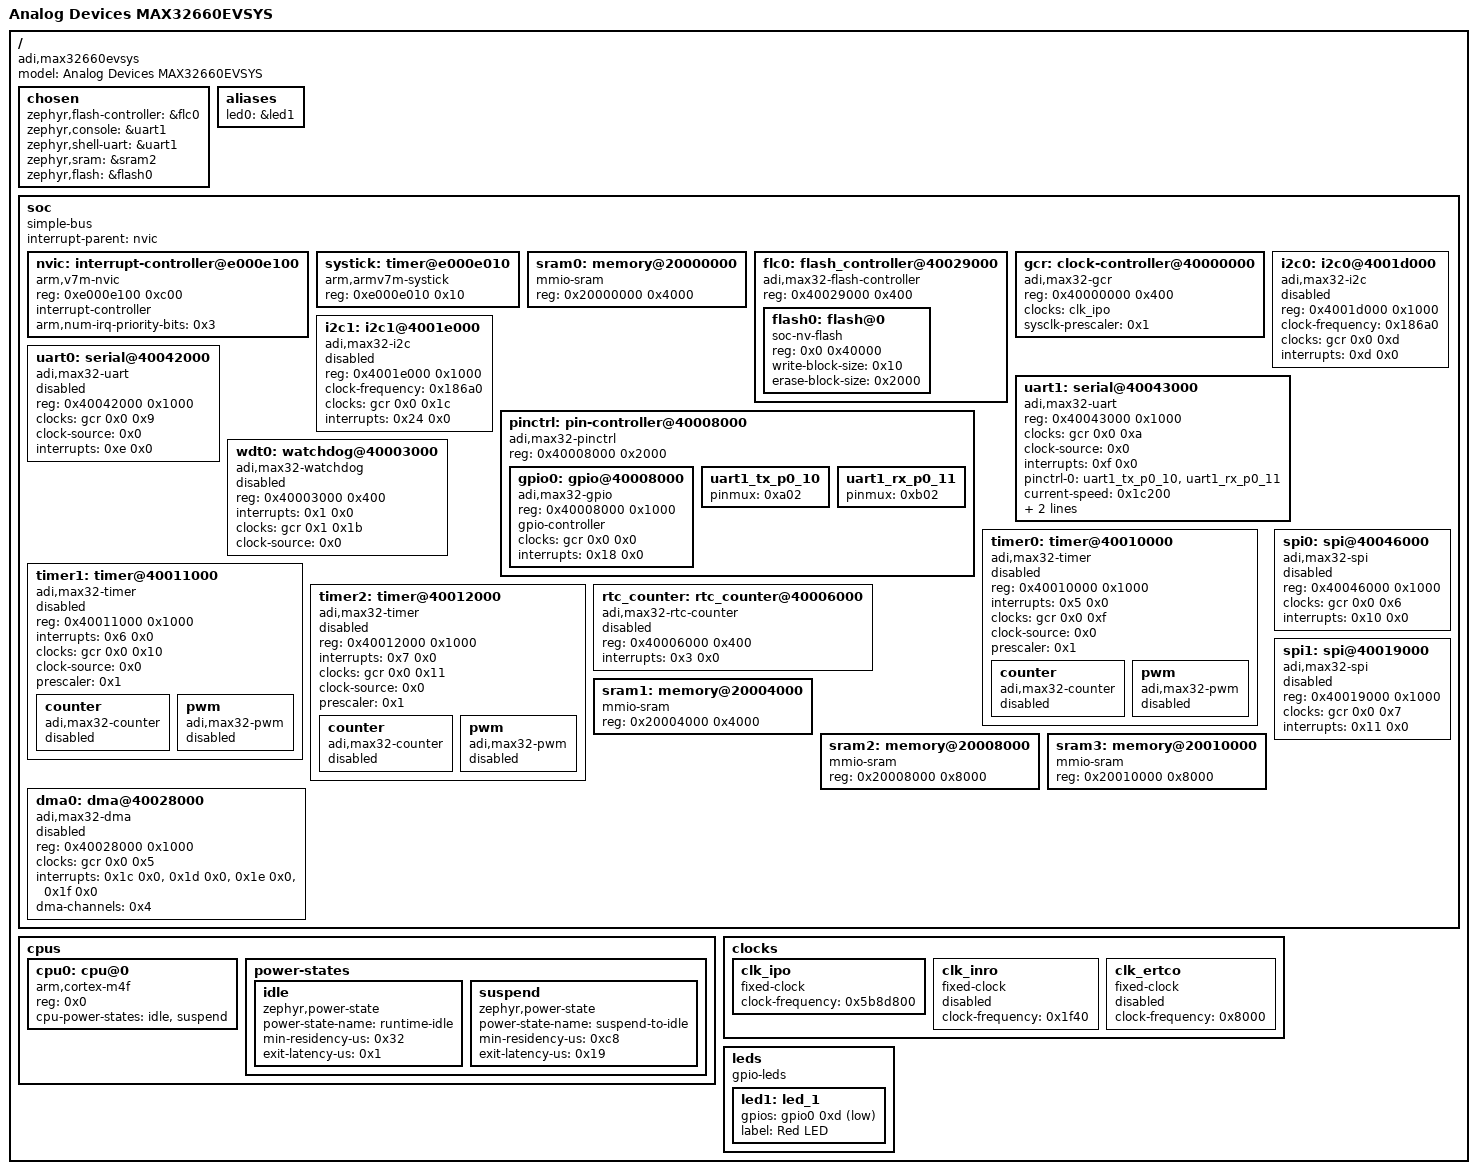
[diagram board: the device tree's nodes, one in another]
/dts-v1/;

/* node '/' defined in zephyr/dts/common/skeleton.dtsi:9 */
/ {
	#address-cells = < 0x1 >;               /* in zephyr/dts/common/skeleton.dtsi:10 */
	#size-cells = < 0x1 >;                  /* in zephyr/dts/common/skeleton.dtsi:11 */
	model = "Analog Devices MAX32660EVSYS"; /* in zephyr/boards/adi/max32660evsys/max32660evsys.dts:15 */
	compatible = "adi,max32660evsys";       /* in zephyr/boards/adi/max32660evsys/max32660evsys.dts:16 */

	/* node '/chosen' defined in zephyr/dts/common/skeleton.dtsi:13 */
	chosen {
		zephyr,flash-controller = &flc0; /* in zephyr/dts/arm/adi/max32/max32xxx.dtsi:18 */
		zephyr,console = &uart1;         /* in zephyr/boards/adi/max32660evsys/max32660evsys.dts:19 */
		zephyr,shell-uart = &uart1;      /* in zephyr/boards/adi/max32660evsys/max32660evsys.dts:20 */
		zephyr,sram = &sram2;            /* in zephyr/boards/adi/max32660evsys/max32660evsys.dts:21 */
		zephyr,flash = &flash0;          /* in zephyr/boards/adi/max32660evsys/max32660evsys.dts:22 */
	};

	/* node '/aliases' defined in zephyr/dts/common/skeleton.dtsi:15 */
	aliases {
		led0 = &led1; /* in zephyr/boards/adi/max32660evsys/max32660evsys.dts:36 */
	};

	/* node '/soc' defined in zephyr/dts/arm/armv7-m.dtsi:6 */
	soc {
		#address-cells = < 0x1 >;     /* in zephyr/dts/arm/armv7-m.dtsi:7 */
		#size-cells = < 0x1 >;        /* in zephyr/dts/arm/armv7-m.dtsi:8 */
		compatible = "simple-bus";    /* in zephyr/dts/arm/armv7-m.dtsi:9 */
		interrupt-parent = < &nvic >; /* in zephyr/dts/arm/armv7-m.dtsi:10 */
		ranges;                       /* in zephyr/dts/arm/armv7-m.dtsi:11 */

		/* node '/soc/interrupt-controller@e000e100' defined in zephyr/dts/arm/armv7-m.dtsi:13 */
		nvic: interrupt-controller@e000e100 {
			#address-cells = < 0x1 >;            /* in zephyr/dts/arm/armv7-m.dtsi:14 */
			compatible = "arm,v7m-nvic";         /* in zephyr/dts/arm/armv7-m.dtsi:15 */
			reg = < 0xe000e100 0xc00 >;          /* in zephyr/dts/arm/armv7-m.dtsi:16 */
			interrupt-controller;                /* in zephyr/dts/arm/armv7-m.dtsi:17 */
			#interrupt-cells = < 0x2 >;          /* in zephyr/dts/arm/armv7-m.dtsi:18 */
			arm,num-irq-priority-bits = < 0x3 >; /* in zephyr/dts/arm/adi/max32/max32xxx.dtsi:337 */
			phandle = < 0x1 >;                   /* in zephyr/dts/arm/armv7-m.dtsi:10 */
		};

		/* node '/soc/timer@e000e010' defined in zephyr/dts/arm/armv7-m.dtsi:21 */
		systick: timer@e000e010 {
			compatible = "arm,armv7m-systick"; /* in zephyr/dts/arm/armv7-m.dtsi:22 */
			reg = < 0xe000e010 0x10 >;         /* in zephyr/dts/arm/armv7-m.dtsi:23 */
		};

		/* node '/soc/memory@20000000' defined in zephyr/dts/arm/adi/max32/max32xxx.dtsi:98 */
		sram0: memory@20000000 {
			compatible = "mmio-sram";    /* in zephyr/dts/arm/adi/max32/max32xxx.dtsi:99 */
			reg = < 0x20000000 0x4000 >; /* in zephyr/dts/arm/adi/max32/max32660.dtsi:16 */
		};

		/* node '/soc/flash_controller@40029000' defined in zephyr/dts/arm/adi/max32/max32xxx.dtsi:103 */
		flc0: flash_controller@40029000 {
			compatible = "adi,max32-flash-controller"; /* in zephyr/dts/arm/adi/max32/max32xxx.dtsi:104 */
			reg = < 0x40029000 0x400 >;                /* in zephyr/dts/arm/adi/max32/max32xxx.dtsi:105 */
			#address-cells = < 0x1 >;                  /* in zephyr/dts/arm/adi/max32/max32xxx.dtsi:107 */
			#size-cells = < 0x1 >;                     /* in zephyr/dts/arm/adi/max32/max32xxx.dtsi:108 */
			status = "okay";                           /* in zephyr/dts/arm/adi/max32/max32xxx.dtsi:109 */

			/* node '/soc/flash_controller@40029000/flash@0' defined in zephyr/dts/arm/adi/max32/max32660.dtsi:31 */
			flash0: flash@0 {
				compatible = "soc-nv-flash";   /* in zephyr/dts/arm/adi/max32/max32660.dtsi:32 */
				reg = < 0x0 0x40000 >;         /* in zephyr/dts/arm/adi/max32/max32660.dtsi:33 */
				write-block-size = < 0x10 >;   /* in zephyr/dts/arm/adi/max32/max32660.dtsi:34 */
				erase-block-size = < 0x2000 >; /* in zephyr/dts/arm/adi/max32/max32660.dtsi:35 */
			};
		};

		/* node '/soc/clock-controller@40000000' defined in zephyr/dts/arm/adi/max32/max32xxx.dtsi:119 */
		gcr: clock-controller@40000000 {
			reg = < 0x40000000 0x400 >;   /* in zephyr/dts/arm/adi/max32/max32xxx.dtsi:120 */
			compatible = "adi,max32-gcr"; /* in zephyr/dts/arm/adi/max32/max32xxx.dtsi:121 */
			#clock-cells = < 0x2 >;       /* in zephyr/dts/arm/adi/max32/max32xxx.dtsi:122 */
			clocks = < &clk_ipo >;        /* in zephyr/dts/arm/adi/max32/max32xxx.dtsi:123 */
			sysclk-prescaler = < 0x1 >;   /* in zephyr/dts/arm/adi/max32/max32xxx.dtsi:124 */
			status = "okay";              /* in zephyr/dts/arm/adi/max32/max32xxx.dtsi:125 */
			phandle = < 0x3 >;            /* in zephyr/dts/arm/adi/max32/max32xxx.dtsi:134 */
		};

		/* node '/soc/i2c0@4001d000' defined in zephyr/dts/arm/adi/max32/max32xxx.dtsi:128 */
		i2c0: i2c0@4001d000 {
			compatible = "adi,max32-i2c";  /* in zephyr/dts/arm/adi/max32/max32xxx.dtsi:129 */
			reg = < 0x4001d000 0x1000 >;   /* in zephyr/dts/arm/adi/max32/max32xxx.dtsi:130 */
			#address-cells = < 0x1 >;      /* in zephyr/dts/arm/adi/max32/max32xxx.dtsi:131 */
			#size-cells = < 0x0 >;         /* in zephyr/dts/arm/adi/max32/max32xxx.dtsi:132 */
			clock-frequency = < 0x186a0 >; /* in zephyr/dts/arm/adi/max32/max32xxx.dtsi:133 */
			clocks = < &gcr 0x0 0xd >;     /* in zephyr/dts/arm/adi/max32/max32xxx.dtsi:134 */
			interrupts = < 0xd 0x0 >;      /* in zephyr/dts/arm/adi/max32/max32xxx.dtsi:135 */
			status = "disabled";           /* in zephyr/dts/arm/adi/max32/max32xxx.dtsi:136 */
		};

		/* node '/soc/i2c1@4001e000' defined in zephyr/dts/arm/adi/max32/max32xxx.dtsi:139 */
		i2c1: i2c1@4001e000 {
			compatible = "adi,max32-i2c";  /* in zephyr/dts/arm/adi/max32/max32xxx.dtsi:140 */
			reg = < 0x4001e000 0x1000 >;   /* in zephyr/dts/arm/adi/max32/max32xxx.dtsi:141 */
			#address-cells = < 0x1 >;      /* in zephyr/dts/arm/adi/max32/max32xxx.dtsi:142 */
			#size-cells = < 0x0 >;         /* in zephyr/dts/arm/adi/max32/max32xxx.dtsi:143 */
			clock-frequency = < 0x186a0 >; /* in zephyr/dts/arm/adi/max32/max32xxx.dtsi:144 */
			clocks = < &gcr 0x0 0x1c >;    /* in zephyr/dts/arm/adi/max32/max32xxx.dtsi:145 */
			interrupts = < 0x24 0x0 >;     /* in zephyr/dts/arm/adi/max32/max32xxx.dtsi:146 */
			status = "disabled";           /* in zephyr/dts/arm/adi/max32/max32xxx.dtsi:147 */
		};

		/* node '/soc/pin-controller@40008000' defined in zephyr/dts/arm/adi/max32/max32xxx.dtsi:161 */
		pinctrl: pin-controller@40008000 {
			compatible = "adi,max32-pinctrl"; /* in zephyr/dts/arm/adi/max32/max32xxx.dtsi:162 */
			#address-cells = < 0x1 >;         /* in zephyr/dts/arm/adi/max32/max32xxx.dtsi:163 */
			#size-cells = < 0x1 >;            /* in zephyr/dts/arm/adi/max32/max32xxx.dtsi:164 */
			reg = < 0x40008000 0x2000 >;      /* in zephyr/dts/arm/adi/max32/max32xxx.dtsi:165 */

			/* node '/soc/pin-controller@40008000/gpio@40008000' defined in zephyr/dts/arm/adi/max32/max32xxx.dtsi:167 */
			gpio0: gpio@40008000 {
				reg = < 0x40008000 0x1000 >;   /* in zephyr/dts/arm/adi/max32/max32xxx.dtsi:168 */
				compatible = "adi,max32-gpio"; /* in zephyr/dts/arm/adi/max32/max32xxx.dtsi:169 */
				gpio-controller;               /* in zephyr/dts/arm/adi/max32/max32xxx.dtsi:170 */
				#gpio-cells = < 0x2 >;         /* in zephyr/dts/arm/adi/max32/max32xxx.dtsi:171 */
				clocks = < &gcr 0x0 0x0 >;     /* in zephyr/dts/arm/adi/max32/max32xxx.dtsi:172 */
				interrupts = < 0x18 0x0 >;     /* in zephyr/dts/arm/adi/max32/max32xxx.dtsi:173 */
				status = "okay";               /* in zephyr/boards/adi/max32660evsys/max32660evsys.dts:54 */
				phandle = < 0x8 >;             /* in zephyr/boards/adi/max32660evsys/max32660evsys.dts:29 */
			};

			/* node '/soc/pin-controller@40008000/uart1_tx_p0_10' defined in zephyr/dts/arm/adi/max32/max32660-pinctrl.dtsi:120 */
			uart1_tx_p0_10: uart1_tx_p0_10 {
				pinmux = < 0xa02 >; /* in zephyr/dts/arm/adi/max32/max32660-pinctrl.dtsi:121 */
				phandle = < 0x4 >;  /* in zephyr/boards/adi/max32660evsys/max32660evsys.dts:41 */
			};

			/* node '/soc/pin-controller@40008000/uart1_rx_p0_11' defined in zephyr/dts/arm/adi/max32/max32660-pinctrl.dtsi:128 */
			uart1_rx_p0_11: uart1_rx_p0_11 {
				pinmux = < 0xb02 >; /* in zephyr/dts/arm/adi/max32/max32660-pinctrl.dtsi:129 */
				phandle = < 0x5 >;  /* in zephyr/boards/adi/max32660evsys/max32660evsys.dts:41 */
			};
		};

		/* node '/soc/serial@40042000' defined in zephyr/dts/arm/adi/max32/max32xxx.dtsi:188 */
		uart0: serial@40042000 {
			compatible = "adi,max32-uart"; /* in zephyr/dts/arm/adi/max32/max32xxx.dtsi:189 */
			reg = < 0x40042000 0x1000 >;   /* in zephyr/dts/arm/adi/max32/max32xxx.dtsi:190 */
			clocks = < &gcr 0x0 0x9 >;     /* in zephyr/dts/arm/adi/max32/max32xxx.dtsi:191 */
			clock-source = < 0x0 >;        /* in zephyr/dts/arm/adi/max32/max32xxx.dtsi:192 */
			interrupts = < 0xe 0x0 >;      /* in zephyr/dts/arm/adi/max32/max32xxx.dtsi:193 */
			status = "disabled";           /* in zephyr/dts/arm/adi/max32/max32xxx.dtsi:194 */
		};

		/* node '/soc/serial@40043000' defined in zephyr/dts/arm/adi/max32/max32xxx.dtsi:197 */
		uart1: serial@40043000 {
			compatible = "adi,max32-uart";                   /* in zephyr/dts/arm/adi/max32/max32xxx.dtsi:198 */
			reg = < 0x40043000 0x1000 >;                     /* in zephyr/dts/arm/adi/max32/max32xxx.dtsi:199 */
			clocks = < &gcr 0x0 0xa >;                       /* in zephyr/dts/arm/adi/max32/max32xxx.dtsi:200 */
			clock-source = < 0x0 >;                          /* in zephyr/dts/arm/adi/max32/max32xxx.dtsi:201 */
			interrupts = < 0xf 0x0 >;                        /* in zephyr/dts/arm/adi/max32/max32xxx.dtsi:202 */
			pinctrl-0 = < &uart1_tx_p0_10 &uart1_rx_p0_11 >; /* in zephyr/boards/adi/max32660evsys/max32660evsys.dts:41 */
			pinctrl-names = "default";                       /* in zephyr/boards/adi/max32660evsys/max32660evsys.dts:42 */
			current-speed = < 0x1c200 >;                     /* in zephyr/boards/adi/max32660evsys/max32660evsys.dts:43 */
			data-bits = < 0x8 >;                             /* in zephyr/boards/adi/max32660evsys/max32660evsys.dts:44 */
			parity = "none";                                 /* in zephyr/boards/adi/max32660evsys/max32660evsys.dts:45 */
			status = "okay";                                 /* in zephyr/boards/adi/max32660evsys/max32660evsys.dts:46 */
		};

		/* node '/soc/watchdog@40003000' defined in zephyr/dts/arm/adi/max32/max32xxx.dtsi:222 */
		wdt0: watchdog@40003000 {
			compatible = "adi,max32-watchdog"; /* in zephyr/dts/arm/adi/max32/max32xxx.dtsi:223 */
			reg = < 0x40003000 0x400 >;        /* in zephyr/dts/arm/adi/max32/max32xxx.dtsi:224 */
			interrupts = < 0x1 0x0 >;          /* in zephyr/dts/arm/adi/max32/max32xxx.dtsi:225 */
			clocks = < &gcr 0x1 0x1b >;        /* in zephyr/dts/arm/adi/max32/max32xxx.dtsi:226 */
			clock-source = < 0x0 >;            /* in zephyr/dts/arm/adi/max32/max32xxx.dtsi:227 */
			status = "disabled";               /* in zephyr/dts/arm/adi/max32/max32xxx.dtsi:228 */
		};

		/* node '/soc/timer@40010000' defined in zephyr/dts/arm/adi/max32/max32xxx.dtsi:243 */
		timer0: timer@40010000 {
			compatible = "adi,max32-timer"; /* in zephyr/dts/arm/adi/max32/max32xxx.dtsi:244 */
			reg = < 0x40010000 0x1000 >;    /* in zephyr/dts/arm/adi/max32/max32xxx.dtsi:245 */
			interrupts = < 0x5 0x0 >;       /* in zephyr/dts/arm/adi/max32/max32xxx.dtsi:246 */
			status = "disabled";            /* in zephyr/dts/arm/adi/max32/max32xxx.dtsi:247 */
			clocks = < &gcr 0x0 0xf >;      /* in zephyr/dts/arm/adi/max32/max32xxx.dtsi:248 */
			clock-source = < 0x0 >;         /* in zephyr/dts/arm/adi/max32/max32xxx.dtsi:249 */
			prescaler = < 0x1 >;            /* in zephyr/dts/arm/adi/max32/max32xxx.dtsi:250 */

			/* node '/soc/timer@40010000/counter' defined in zephyr/dts/arm/adi/max32/max32xxx.dtsi:252 */
			counter {
				compatible = "adi,max32-counter"; /* in zephyr/dts/arm/adi/max32/max32xxx.dtsi:253 */
				status = "disabled";              /* in zephyr/dts/arm/adi/max32/max32xxx.dtsi:254 */
			};

			/* node '/soc/timer@40010000/pwm' defined in zephyr/dts/arm/adi/max32/max32xxx.dtsi:257 */
			pwm {
				compatible = "adi,max32-pwm"; /* in zephyr/dts/arm/adi/max32/max32xxx.dtsi:258 */
				status = "disabled";          /* in zephyr/dts/arm/adi/max32/max32xxx.dtsi:259 */
				#pwm-cells = < 0x3 >;         /* in zephyr/dts/arm/adi/max32/max32xxx.dtsi:260 */
			};
		};

		/* node '/soc/timer@40011000' defined in zephyr/dts/arm/adi/max32/max32xxx.dtsi:264 */
		timer1: timer@40011000 {
			compatible = "adi,max32-timer"; /* in zephyr/dts/arm/adi/max32/max32xxx.dtsi:265 */
			reg = < 0x40011000 0x1000 >;    /* in zephyr/dts/arm/adi/max32/max32xxx.dtsi:266 */
			interrupts = < 0x6 0x0 >;       /* in zephyr/dts/arm/adi/max32/max32xxx.dtsi:267 */
			status = "disabled";            /* in zephyr/dts/arm/adi/max32/max32xxx.dtsi:268 */
			clocks = < &gcr 0x0 0x10 >;     /* in zephyr/dts/arm/adi/max32/max32xxx.dtsi:269 */
			clock-source = < 0x0 >;         /* in zephyr/dts/arm/adi/max32/max32xxx.dtsi:270 */
			prescaler = < 0x1 >;            /* in zephyr/dts/arm/adi/max32/max32xxx.dtsi:271 */

			/* node '/soc/timer@40011000/counter' defined in zephyr/dts/arm/adi/max32/max32xxx.dtsi:273 */
			counter {
				compatible = "adi,max32-counter"; /* in zephyr/dts/arm/adi/max32/max32xxx.dtsi:274 */
				status = "disabled";              /* in zephyr/dts/arm/adi/max32/max32xxx.dtsi:275 */
			};

			/* node '/soc/timer@40011000/pwm' defined in zephyr/dts/arm/adi/max32/max32xxx.dtsi:278 */
			pwm {
				compatible = "adi,max32-pwm"; /* in zephyr/dts/arm/adi/max32/max32xxx.dtsi:279 */
				status = "disabled";          /* in zephyr/dts/arm/adi/max32/max32xxx.dtsi:280 */
				#pwm-cells = < 0x3 >;         /* in zephyr/dts/arm/adi/max32/max32xxx.dtsi:281 */
			};
		};

		/* node '/soc/timer@40012000' defined in zephyr/dts/arm/adi/max32/max32xxx.dtsi:285 */
		timer2: timer@40012000 {
			compatible = "adi,max32-timer"; /* in zephyr/dts/arm/adi/max32/max32xxx.dtsi:286 */
			reg = < 0x40012000 0x1000 >;    /* in zephyr/dts/arm/adi/max32/max32xxx.dtsi:287 */
			interrupts = < 0x7 0x0 >;       /* in zephyr/dts/arm/adi/max32/max32xxx.dtsi:288 */
			status = "disabled";            /* in zephyr/dts/arm/adi/max32/max32xxx.dtsi:289 */
			clocks = < &gcr 0x0 0x11 >;     /* in zephyr/dts/arm/adi/max32/max32xxx.dtsi:290 */
			clock-source = < 0x0 >;         /* in zephyr/dts/arm/adi/max32/max32xxx.dtsi:291 */
			prescaler = < 0x1 >;            /* in zephyr/dts/arm/adi/max32/max32xxx.dtsi:292 */

			/* node '/soc/timer@40012000/counter' defined in zephyr/dts/arm/adi/max32/max32xxx.dtsi:294 */
			counter {
				compatible = "adi,max32-counter"; /* in zephyr/dts/arm/adi/max32/max32xxx.dtsi:295 */
				status = "disabled";              /* in zephyr/dts/arm/adi/max32/max32xxx.dtsi:296 */
			};

			/* node '/soc/timer@40012000/pwm' defined in zephyr/dts/arm/adi/max32/max32xxx.dtsi:299 */
			pwm {
				compatible = "adi,max32-pwm"; /* in zephyr/dts/arm/adi/max32/max32xxx.dtsi:300 */
				status = "disabled";          /* in zephyr/dts/arm/adi/max32/max32xxx.dtsi:301 */
				#pwm-cells = < 0x3 >;         /* in zephyr/dts/arm/adi/max32/max32xxx.dtsi:302 */
			};
		};

		/* node '/soc/rtc_counter@40006000' defined in zephyr/dts/arm/adi/max32/max32xxx.dtsi:327 */
		rtc_counter: rtc_counter@40006000 {
			compatible = "adi,max32-rtc-counter"; /* in zephyr/dts/arm/adi/max32/max32xxx.dtsi:328 */
			reg = < 0x40006000 0x400 >;           /* in zephyr/dts/arm/adi/max32/max32xxx.dtsi:329 */
			interrupts = < 0x3 0x0 >;             /* in zephyr/dts/arm/adi/max32/max32xxx.dtsi:330 */
			status = "disabled";                  /* in zephyr/dts/arm/adi/max32/max32xxx.dtsi:331 */
		};

		/* node '/soc/memory@20004000' defined in zephyr/dts/arm/adi/max32/max32660.dtsi:46 */
		sram1: memory@20004000 {
			compatible = "mmio-sram";    /* in zephyr/dts/arm/adi/max32/max32660.dtsi:47 */
			reg = < 0x20004000 0x4000 >; /* in zephyr/dts/arm/adi/max32/max32660.dtsi:48 */
		};

		/* node '/soc/memory@20008000' defined in zephyr/dts/arm/adi/max32/max32660.dtsi:51 */
		sram2: memory@20008000 {
			compatible = "mmio-sram";    /* in zephyr/dts/arm/adi/max32/max32660.dtsi:52 */
			reg = < 0x20008000 0x8000 >; /* in zephyr/dts/arm/adi/max32/max32660.dtsi:53 */
		};

		/* node '/soc/memory@20010000' defined in zephyr/dts/arm/adi/max32/max32660.dtsi:56 */
		sram3: memory@20010000 {
			compatible = "mmio-sram";    /* in zephyr/dts/arm/adi/max32/max32660.dtsi:57 */
			reg = < 0x20010000 0x8000 >; /* in zephyr/dts/arm/adi/max32/max32660.dtsi:58 */
		};

		/* node '/soc/dma@40028000' defined in zephyr/dts/arm/adi/max32/max32660.dtsi:61 */
		dma0: dma@40028000 {
			compatible = "adi,max32-dma"; /* in zephyr/dts/arm/adi/max32/max32660.dtsi:62 */
			reg = < 0x40028000 0x1000 >;  /* in zephyr/dts/arm/adi/max32/max32660.dtsi:63 */
			clocks = < &gcr 0x0 0x5 >;    /* in zephyr/dts/arm/adi/max32/max32660.dtsi:64 */
			interrupts = < 0x1c 0x0 >,
			             < 0x1d 0x0 >,
			             < 0x1e 0x0 >,
			             < 0x1f 0x0 >;    /* in zephyr/dts/arm/adi/max32/max32660.dtsi:65 */
			dma-channels = < 0x4 >;       /* in zephyr/dts/arm/adi/max32/max32660.dtsi:66 */
			status = "disabled";          /* in zephyr/dts/arm/adi/max32/max32660.dtsi:67 */
			#dma-cells = < 0x2 >;         /* in zephyr/dts/arm/adi/max32/max32660.dtsi:68 */
		};

		/* node '/soc/spi@40046000' defined in zephyr/dts/arm/adi/max32/max32660.dtsi:71 */
		spi0: spi@40046000 {
			compatible = "adi,max32-spi"; /* in zephyr/dts/arm/adi/max32/max32660.dtsi:72 */
			reg = < 0x40046000 0x1000 >;  /* in zephyr/dts/arm/adi/max32/max32660.dtsi:73 */
			#address-cells = < 0x1 >;     /* in zephyr/dts/arm/adi/max32/max32660.dtsi:74 */
			#size-cells = < 0x0 >;        /* in zephyr/dts/arm/adi/max32/max32660.dtsi:75 */
			clocks = < &gcr 0x0 0x6 >;    /* in zephyr/dts/arm/adi/max32/max32660.dtsi:76 */
			interrupts = < 0x10 0x0 >;    /* in zephyr/dts/arm/adi/max32/max32660.dtsi:77 */
			status = "disabled";          /* in zephyr/dts/arm/adi/max32/max32660.dtsi:78 */
		};

		/* node '/soc/spi@40019000' defined in zephyr/dts/arm/adi/max32/max32660.dtsi:81 */
		spi1: spi@40019000 {
			compatible = "adi,max32-spi"; /* in zephyr/dts/arm/adi/max32/max32660.dtsi:82 */
			reg = < 0x40019000 0x1000 >;  /* in zephyr/dts/arm/adi/max32/max32660.dtsi:83 */
			#address-cells = < 0x1 >;     /* in zephyr/dts/arm/adi/max32/max32660.dtsi:84 */
			#size-cells = < 0x0 >;        /* in zephyr/dts/arm/adi/max32/max32660.dtsi:85 */
			clocks = < &gcr 0x0 0x7 >;    /* in zephyr/dts/arm/adi/max32/max32660.dtsi:86 */
			interrupts = < 0x11 0x0 >;    /* in zephyr/dts/arm/adi/max32/max32660.dtsi:87 */
			status = "disabled";          /* in zephyr/dts/arm/adi/max32/max32660.dtsi:88 */
		};
	};

	/* node '/cpus' defined in zephyr/dts/arm/adi/max32/max32xxx.dtsi:21 */
	cpus {
		#address-cells = < 0x1 >; /* in zephyr/dts/arm/adi/max32/max32xxx.dtsi:22 */
		#size-cells = < 0x0 >;    /* in zephyr/dts/arm/adi/max32/max32xxx.dtsi:23 */

		/* node '/cpus/cpu@0' defined in zephyr/dts/arm/adi/max32/max32xxx.dtsi:25 */
		cpu0: cpu@0 {
			device_type = "cpu";                   /* in zephyr/dts/arm/adi/max32/max32xxx.dtsi:26 */
			compatible = "arm,cortex-m4f";         /* in zephyr/dts/arm/adi/max32/max32xxx.dtsi:27 */
			reg = < 0x0 >;                         /* in zephyr/dts/arm/adi/max32/max32xxx.dtsi:28 */
			cpu-power-states = < &idle &suspend >; /* in zephyr/dts/arm/adi/max32/max32xxx.dtsi:29 */
		};

		/* node '/cpus/power-states' defined in zephyr/dts/arm/adi/max32/max32xxx.dtsi:32 */
		power-states {

			/* node '/cpus/power-states/idle' defined in zephyr/dts/arm/adi/max32/max32xxx.dtsi:34 */
			idle: idle {
				compatible = "zephyr,power-state"; /* in zephyr/dts/arm/adi/max32/max32xxx.dtsi:35 */
				power-state-name = "runtime-idle"; /* in zephyr/dts/arm/adi/max32/max32xxx.dtsi:36 */
				min-residency-us = < 0x32 >;       /* in zephyr/dts/arm/adi/max32/max32xxx.dtsi:37 */
				exit-latency-us = < 0x1 >;         /* in zephyr/dts/arm/adi/max32/max32xxx.dtsi:39 */
				phandle = < 0x6 >;                 /* in zephyr/dts/arm/adi/max32/max32xxx.dtsi:29 */
			};

			/* node '/cpus/power-states/suspend' defined in zephyr/dts/arm/adi/max32/max32xxx.dtsi:43 */
			suspend: suspend {
				compatible = "zephyr,power-state";    /* in zephyr/dts/arm/adi/max32/max32xxx.dtsi:44 */
				power-state-name = "suspend-to-idle"; /* in zephyr/dts/arm/adi/max32/max32xxx.dtsi:45 */
				min-residency-us = < 0xc8 >;          /* in zephyr/dts/arm/adi/max32/max32xxx.dtsi:46 */
				exit-latency-us = < 0x19 >;           /* in zephyr/dts/arm/adi/max32/max32xxx.dtsi:48 */
				phandle = < 0x7 >;                    /* in zephyr/dts/arm/adi/max32/max32xxx.dtsi:29 */
			};
		};
	};

	/* node '/clocks' defined in zephyr/dts/arm/adi/max32/max32xxx.dtsi:53 */
	clocks {

		/* node '/clocks/clk_ipo' defined in zephyr/dts/arm/adi/max32/max32xxx.dtsi:54 */
		clk_ipo: clk_ipo {
			compatible = "fixed-clock";      /* in zephyr/dts/arm/adi/max32/max32xxx.dtsi:55 */
			#clock-cells = < 0x0 >;          /* in zephyr/dts/arm/adi/max32/max32xxx.dtsi:56 */
			clock-frequency = < 0x5b8d800 >; /* in zephyr/dts/arm/adi/max32/max32660.dtsi:12 */
			status = "okay";                 /* in zephyr/boards/adi/max32660evsys/max32660evsys.dts:50 */
			phandle = < 0x2 >;               /* in zephyr/dts/arm/adi/max32/max32xxx.dtsi:123 */
		};

		/* node '/clocks/clk_inro' defined in zephyr/dts/arm/adi/max32/max32xxx.dtsi:68 */
		clk_inro: clk_inro {
			compatible = "fixed-clock";   /* in zephyr/dts/arm/adi/max32/max32xxx.dtsi:69 */
			#clock-cells = < 0x0 >;       /* in zephyr/dts/arm/adi/max32/max32xxx.dtsi:70 */
			clock-frequency = < 0x1f40 >; /* in zephyr/dts/arm/adi/max32/max32xxx.dtsi:71 */
			status = "disabled";          /* in zephyr/dts/arm/adi/max32/max32xxx.dtsi:72 */
		};

		/* node '/clocks/clk_ertco' defined in zephyr/dts/arm/adi/max32/max32xxx.dtsi:82 */
		clk_ertco: clk_ertco {
			compatible = "fixed-clock";   /* in zephyr/dts/arm/adi/max32/max32xxx.dtsi:83 */
			#clock-cells = < 0x0 >;       /* in zephyr/dts/arm/adi/max32/max32xxx.dtsi:84 */
			clock-frequency = < 0x8000 >; /* in zephyr/dts/arm/adi/max32/max32xxx.dtsi:85 */
			status = "disabled";          /* in zephyr/dts/arm/adi/max32/max32xxx.dtsi:86 */
		};
	};

	/* node '/leds' defined in zephyr/boards/adi/max32660evsys/max32660evsys.dts:25 */
	leds {
		compatible = "gpio-leds"; /* in zephyr/boards/adi/max32660evsys/max32660evsys.dts:26 */

		/* node '/leds/led_1' defined in zephyr/boards/adi/max32660evsys/max32660evsys.dts:28 */
		led1: led_1 {
			gpios = < &gpio0 0xd 0x1 >; /* in zephyr/boards/adi/max32660evsys/max32660evsys.dts:29 */
			label = "Red LED";          /* in zephyr/boards/adi/max32660evsys/max32660evsys.dts:30 */
		};
	};
};
